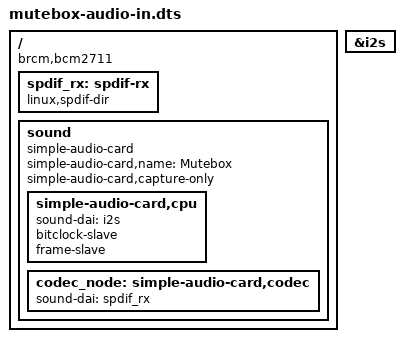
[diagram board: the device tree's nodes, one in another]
/dts-v1/;
/plugin/;
/ {
    compatible = "brcm,bcm2711";

    fragment@0 {
        target = <&i2s>;
        __overlay__ {
            status = "okay";
            #sound-dai-cells = <0>;
        };
    };

    fragment@1 {
        target-path = "/";
        __overlay__ {
            spdif_rx: spdif-rx {
                compatible = "linux,spdif-dir";
                #sound-dai-cells = <0>;
                status = "okay";
            };

            sound {
                compatible = "simple-audio-card";
                simple-audio-card,name = "Mutebox";
                simple-audio-card,capture-only;

                simple-audio-card,cpu {
                    sound-dai = <&i2s>;
                    bitclock-slave;
                    frame-slave;
                };

                codec_node: simple-audio-card,codec {
                    sound-dai = <&spdif_rx>;
                };
            };
        };
    };
};
